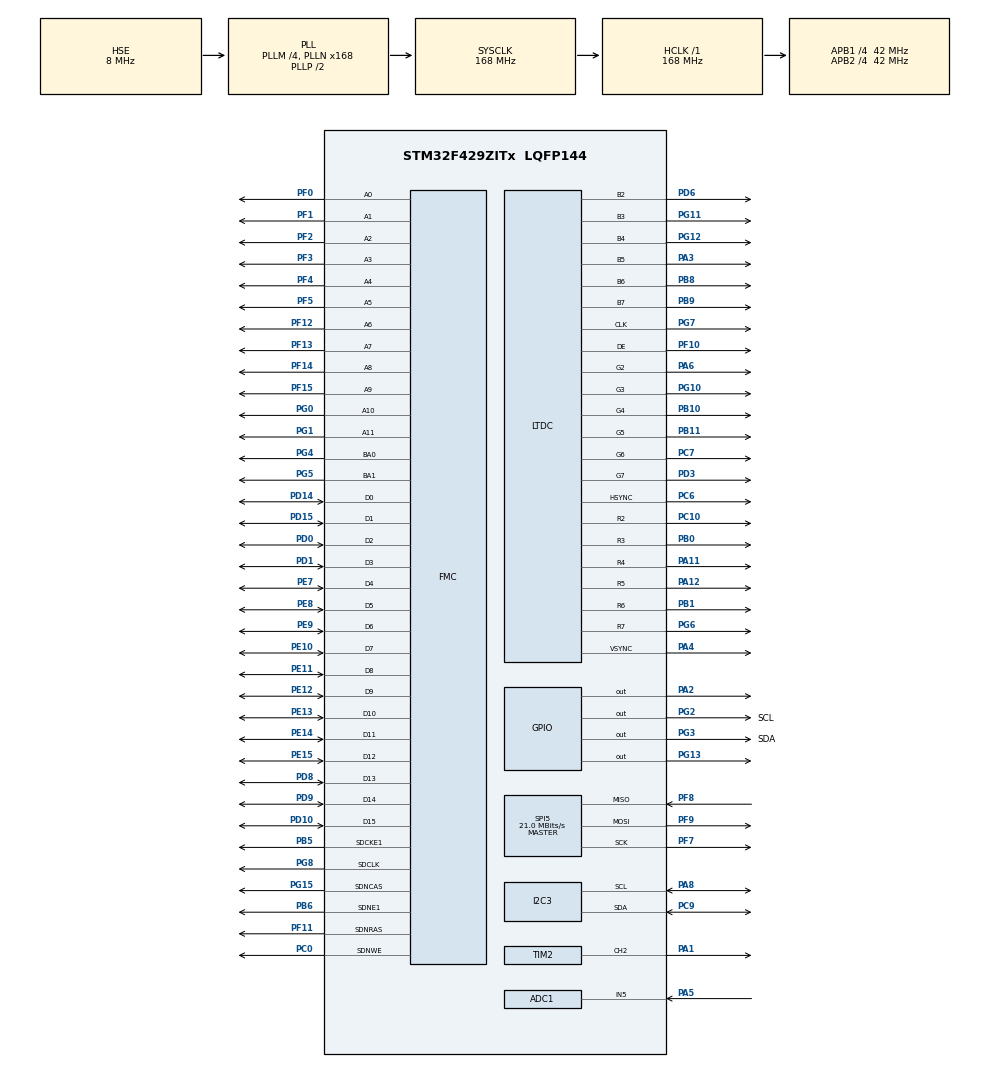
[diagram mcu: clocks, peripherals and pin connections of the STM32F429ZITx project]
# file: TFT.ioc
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ADC1.Channel-12\#ChannelRegularConversion=ADC_CHANNEL_5
ADC1.ClockPrescaler=ADC_CLOCK_SYNC_PCLK_DIV8
ADC1.NbrOfConversionFlag=1
ADC1.Rank-12\#ChannelRegularConversion=1
ADC1.SamplingTime-12\#ChannelRegularConversion=ADC_SAMPLETIME_15CYCLES
ADC1.ScanConvMode=ENABLE
ADC1.master=1
DMA2D.ColorMode=DMA2D_OUTPUT_RGB565
LTDC.ActiveH=240
LTDC.ActiveW=320
Mcu.Family=STM32F4
Mcu.Name=STM32F429ZITx
Mcu.Package=LQFP144
NVIC.PriorityGroup=NVIC_PRIORITYGROUP_4
NVIC.TIM2_IRQn=true\:0\:0\:false\:false\:true\:true
PA1.GPIO_PuPd=GPIO_NOPULL
PA1.GPIO_Speed=GPIO_SPEED_FREQ_HIGH
PA1.Signal=S_TIM2_CH2
PA11.Mode=RGB666
PA11.Signal=LTDC_R4
PA12.Mode=RGB666
PA12.Signal=LTDC_R5
PA13.Mode=Serial_Wire
PA13.Signal=SYS_JTMS-SWDIO
PA14.Mode=Serial_Wire
PA14.Signal=SYS_JTCK-SWCLK
PA2.Signal=GPIO_Output
PA3.Mode=RGB666
PA3.Signal=LTDC_B5
PA4.Mode=RGB666
PA4.Signal=LTDC_VSYNC
PA5.Signal=ADCx_IN5
PA6.Mode=RGB666
PA6.Signal=LTDC_G2
PA8.Mode=I2C
PA8.Signal=I2C3_SCL
PB0.Mode=RGB666
PB0.Signal=LTDC_R3
PB1.Mode=RGB666
PB1.Signal=LTDC_R6
PB10.Mode=RGB666
PB10.Signal=LTDC_G4
PB11.Mode=RGB666
PB11.Signal=LTDC_G5
PB5.Mode=SdramChipSelect2_1
PB5.Signal=FMC_SDCKE1
PB6.Mode=SdramChipSelect2_1
PB6.Signal=FMC_SDNE1
PB8.Mode=RGB666
PB8.Signal=LTDC_B6
PB9.Mode=RGB666
PB9.Signal=LTDC_B7
PC0.Signal=FMC_SDNWE
PC10.Mode=RGB666
PC10.Signal=LTDC_R2
PC6.Mode=RGB666
PC6.Signal=LTDC_HSYNC
PC7.Mode=RGB666
PC7.Signal=LTDC_G6
PC9.Mode=I2C
PC9.Signal=I2C3_SDA
PD0.Signal=FMC_D2_DA2
PD1.Signal=FMC_D3_DA3
PD10.Signal=FMC_D15_DA15
PD14.Signal=FMC_D0_DA0
PD15.Signal=FMC_D1_DA1
PD3.Mode=RGB666
PD3.Signal=LTDC_G7
PD6.Mode=RGB666
PD6.Signal=LTDC_B2
PD8.Signal=FMC_D13_DA13
PD9.Signal=FMC_D14_DA14
PE10.Signal=FMC_D7_DA7
PE11.Signal=FMC_D8_DA8
PE12.Signal=FMC_D9_DA9
PE13.Signal=FMC_D10_DA10
PE14.Signal=FMC_D11_DA11
PE15.Signal=FMC_D12_DA12
PE7.Signal=FMC_D4_DA4
PE8.Signal=FMC_D5_DA5
PE9.Signal=FMC_D6_DA6
PF0.Signal=FMC_A0
PF1.Signal=FMC_A1
PF10.Mode=RGB666
PF10.Signal=LTDC_DE
PF11.Signal=FMC_SDNRAS
PF12.Signal=FMC_A6
PF13.Signal=FMC_A7
PF14.Signal=FMC_A8
PF15.Signal=FMC_A9
PF2.Signal=FMC_A2
PF3.Signal=FMC_A3
PF4.Signal=FMC_A4
PF5.Signal=FMC_A5
PF7.Mode=Full_Duplex_Master
PF7.Signal=SPI5_SCK
PF8.Mode=Full_Duplex_Master
PF8.Signal=SPI5_MISO
PF9.Mode=Full_Duplex_Master
PF9.Signal=SPI5_MOSI
PG0.Signal=FMC_A10
PG1.Signal=FMC_A11
PG10.Mode=RGB666
PG10.Signal=LTDC_G3
PG11.Mode=RGB666
PG11.Signal=LTDC_B3
PG12.Mode=RGB666
PG12.Signal=LTDC_B4
PG13.Signal=GPIO_Output
PG15.Signal=FMC_SDNCAS
PG2.GPIO_Label=SCL
PG2.Signal=GPIO_Output
PG3.GPIO_Label=SDA
PG3.Signal=GPIO_Output
PG4.Signal=FMC_A14_BA0
PG5.Signal=FMC_A15_BA1
PG6.Mode=RGB666
PG6.Signal=LTDC_R7
PG7.Mode=RGB666
PG7.Signal=LTDC_CLK
PG8.Signal=FMC_SDCLK
PH0/OSC_IN.Mode=HSE-External-Oscillator
PH0/OSC_IN.Signal=RCC_OSC_IN
PH1/OSC_OUT.Mode=HSE-External-Oscillator
PH1/OSC_OUT.Signal=RCC_OSC_OUT
ProjectManager.HeapSize=0x1000
ProjectManager.StackSize=0x1000
ProjectManager.TargetToolchain=MDK-ARM V5
RCC.48MHZClocksFreq_Value=84000000
RCC.AHBFreq_Value=168000000
RCC.APB1CLKDivider=RCC_HCLK_DIV4
RCC.APB1Freq_Value=42000000
RCC.APB1TimFreq_Value=84000000
RCC.APB2CLKDivider=RCC_HCLK_DIV4
RCC.APB2Freq_Value=42000000
RCC.APB2TimFreq_Value=84000000
RCC.CortexFreq_Value=168000000
RCC.HCLKFreq_Value=168000000
RCC.HSE_VALUE=8000000
RCC.HSI_VALUE=16000000
RCC.LSE_VALUE=32768
RCC.PLLM=4
RCC.PLLN=168
RCC.PLLSAIN=216
RCC.PLLSourceVirtual=RCC_PLLSOURCE_HSE
RCC.SYSCLKFreq_VALUE=168000000
RCC.SYSCLKSource=RCC_SYSCLKSOURCE_PLLCLK
RCC.VCOOutputFreq_Value=336000000
SH.ADCx_IN5.0=ADC2_IN5
SH.ADCx_IN5.1=ADC1_IN5,IN5
SH.FMC_A0.0=FMC_A0,12b-sda1
SH.FMC_A1.0=FMC_A1,12b-sda1
SH.FMC_A10.0=FMC_A10,12b-sda1
SH.FMC_A11.0=FMC_A11,12b-sda1
SH.FMC_A14_BA0.0=FMC_BA0,FourSdramBanks1
SH.FMC_A15_BA1.0=FMC_BA1,FourSdramBanks1
SH.FMC_A2.0=FMC_A2,12b-sda1
SH.FMC_A3.0=FMC_A3,12b-sda1
SH.FMC_A4.0=FMC_A4,12b-sda1
SH.FMC_A5.0=FMC_A5,12b-sda1
SH.FMC_A6.0=FMC_A6,12b-sda1
SH.FMC_A7.0=FMC_A7,12b-sda1
SH.FMC_A8.0=FMC_A8,12b-sda1
SH.FMC_A9.0=FMC_A9,12b-sda1
SH.FMC_D0_DA0.0=FMC_D0,sd-16b-d1
SH.FMC_D10_DA10.0=FMC_D10,sd-16b-d1
SH.FMC_D11_DA11.0=FMC_D11,sd-16b-d1
SH.FMC_D12_DA12.0=FMC_D12,sd-16b-d1
SH.FMC_D13_DA13.0=FMC_D13,sd-16b-d1
SH.FMC_D14_DA14.0=FMC_D14,sd-16b-d1
SH.FMC_D15_DA15.0=FMC_D15,sd-16b-d1
SH.FMC_D1_DA1.0=FMC_D1,sd-16b-d1
SH.FMC_D2_DA2.0=FMC_D2,sd-16b-d1
SH.FMC_D3_DA3.0=FMC_D3,sd-16b-d1
SH.FMC_D4_DA4.0=FMC_D4,sd-16b-d1
SH.FMC_D5_DA5.0=FMC_D5,sd-16b-d1
SH.FMC_D6_DA6.0=FMC_D6,sd-16b-d1
SH.FMC_D7_DA7.0=FMC_D7,sd-16b-d1
SH.FMC_D8_DA8.0=FMC_D8,sd-16b-d1
SH.FMC_D9_DA9.0=FMC_D9,sd-16b-d1
SH.FMC_SDCLK.0=FMC_SDCLK,12b-sda1
SH.FMC_SDNCAS.0=FMC_SDNCAS,12b-sda1
SH.FMC_SDNRAS.0=FMC_SDNRAS,12b-sda1
SH.FMC_SDNWE.0=FMC_SDNWE,12b-sda1
SH.S_TIM2_CH2.0=TIM2_CH2,PWM Generation2 CH2
SPI5.CalculateBaudRate=21.0 MBits/s
SPI5.Direction=SPI_DIRECTION_2LINES
SPI5.Mode=SPI_MODE_MASTER
SPI5.VirtualType=VM_MASTER
TIM2.Channel-PWM\ Generation2\ CH2=TIM_CHANNEL_2
TIM2.Period=9
TIM2.Prescaler=420
TIM2.Pulse-PWM\ Generation2\ CH2=50
VP_DMA2D_VS_DMA2D.Mode=DMA2D_Activate
VP_TIM2_VS_ClockSourceINT.Mode=Internal
board=TFT

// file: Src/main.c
/**
  ******************************************************************************
  * @file           : main.c
  * @brief          : Main program body
  ******************************************************************************
  ** This notice applies to any and all portions of this file
  * that are not between comment pairs USER CODE BEGIN and
  * USER CODE END. Other portions of this file, whether
  * inserted by the user or by software development tools
  * are owned by their respective copyright owners.
  *
  * COPYRIGHT(c) 2018 STMicroelectronics
  *
  * Redistribution and use in source and binary forms, with or without modification,
  * are permitted provided that the following conditions are met:
  *   1. Redistributions of source code must retain the above copyright notice,
  *      this list of conditions and the following disclaimer.
  *   2. Redistributions in binary form must reproduce the above copyright notice,
  *      this list of conditions and the following disclaimer in the documentation
  *      and/or other materials provided with the distribution.
  *   3. Neither the name of STMicroelectronics nor the names of its contributors
  *      may be used to endorse or promote products derived from this software
  *      without specific prior written permission.
  *
  * THIS SOFTWARE IS PROVIDED BY THE COPYRIGHT HOLDERS AND CONTRIBUTORS "AS IS"
  * AND ANY EXPRESS OR IMPLIED WARRANTIES, INCLUDING, BUT NOT LIMITED TO, THE
  * IMPLIED WARRANTIES OF MERCHANTABILITY AND FITNESS FOR A PARTICULAR PURPOSE ARE
  * DISCLAIMED. IN NO EVENT SHALL THE COPYRIGHT HOLDER OR CONTRIBUTORS BE LIABLE
  * FOR ANY DIRECT, INDIRECT, INCIDENTAL, SPECIAL, EXEMPLARY, OR CONSEQUENTIAL
  * DAMAGES (INCLUDING, BUT NOT LIMITED TO, PROCUREMENT OF SUBSTITUTE GOODS OR
  * SERVICES; LOSS OF USE, DATA, OR PROFITS; OR BUSINESS INTERRUPTION) HOWEVER
  * CAUSED AND ON ANY THEORY OF LIABILITY, WHETHER IN CONTRACT, STRICT LIABILITY,
  * OR TORT (INCLUDING NEGLIGENCE OR OTHERWISE) ARISING IN ANY WAY OUT OF THE USE
  * OF THIS SOFTWARE, EVEN IF ADVISED OF THE POSSIBILITY OF SUCH DAMAGE.
  *
  ******************************************************************************
  */
#include "main.h"
#include "stm32f4xx_hal.h"
#include "adc.h"
#include "dma2d.h"
#include "i2c.h"
#include "ltdc.h"
#include "spi.h"
#include "tim.h"
#include "gpio.h"
#include "fmc.h"

/* USER CODE BEGIN Includes */

#ifndef P
/*
 * Sets an output pin
 *
 * Parameters
 *  letter - A single letter that identifies the GPIO bus
 *  pin index - A number between 0 and 8 for which pin
 *  value - a binary number that identifies low or high to drive the pin
 *
 * Usage:
 * P(G, 13, 1); // Sets pin PG13 to HIGH
 *
*/
    #define P(l,i,v)    GPIO##l->BSRR = 1<<(i+((!v)*16))
/*
 * Reads a pin from a port, returns 0 or 1
*/
    #define R(l,i)      ((GPIO##l->IDR & (1<<i))>0)
#endif

#include "stm32f429i_discovery_lcd.h"
#include "stm32f429i_discovery_sdram.h"
#include "stm32f429i_discovery_ts.h"
#include "string.h"
#include "i2c_sht15.h"
#include "slider_component.h"
#include "state_machine.h"
/* USER CODE END Includes */

/* USER CODE BEGIN PV */
/* Private variables ---------------------------------------------------------*/

/* USER CODE END PV */

void SystemClock_Config(void);

/* USER CODE BEGIN PFP */
/* Private function prototypes -----------------------------------------------*/

/* USER CODE END PFP */

/* USER CODE BEGIN 0 */
void updatePwmValue() {
	static int manual_pwm = 0;
	static int pwm_state = 0;
	int should_be_1 = (manual_pwm > pot_value/40.0f);

	if (manual_pwm < 100) {
		if (pwm_state == 0 && should_be_1) {
			P(C, 8, 1);
			pwm_state = 1;
		} else if (pwm_state == 1 && !should_be_1) {
			P(C, 8, 0);
			pwm_state = 0;
		}
		manual_pwm++;
	} else {
		manual_pwm = 0;
	}
}

int last_pwm_count; // declared to use in state_machine

void HAL_TIM_PeriodElapsedCallback(TIM_HandleTypeDef *htim)
{
	if(htim == &htim2) {
	static int sum = 0;
	static int interval = 0;
	if (R(C, 8)) {
		sum++;
	}
	interval++;
	if (interval > 100) {
		interval = 0;
		last_pwm_count = sum;
		sum = 0;
	}
	updatePwmValue();
	}
}
/* USER CODE END 0 */

int main(void)
{
  /* USER CODE BEGIN 1 */
TS_StateTypeDef TsState;
ADC_ChannelConfTypeDef sConfig;
  /* USER CODE END 1 */

  /* MCU Configuration----------------------------------------------------------*/

  /* Reset of all peripherals, Initializes the Flash interface and the Systick. */
  HAL_Init();

  /* Configure the system clock */
  SystemClock_Config();

  /* Initialize all configured peripherals */
  MX_GPIO_Init();
  MX_DMA2D_Init();
  MX_LTDC_Init();
  MX_I2C3_Init();
  MX_SPI5_Init();
  MX_FMC_Init();
  MX_TIM2_Init();
  MX_ADC1_Init();
  /* USER CODE BEGIN 2 */

  BSP_LCD_Init();
  BSP_LCD_LayerDefaultInit(LCD_BACKGROUND_LAYER,LCD_FRAME_BUFFER);
  BSP_LCD_LayerDefaultInit(LCD_FOREGROUND_LAYER,LCD_FRAME_BUFFER);
  BSP_LCD_DisplayOn();
  BSP_LCD_SelectLayer(LCD_FOREGROUND_LAYER);
  BSP_TS_Init(240, 320);
  unsigned long last_display_update = HAL_GetTick();
  init_sliders();
	init_state_machine();
	int adc_control = 0;
	HAL_TIM_Base_Start_IT(&htim2);

	GPIO_InitTypeDef GPIO_InitStruct;
	GPIO_InitStruct.Pin = GPIO_PIN_8; // SDA => PG.2
	GPIO_InitStruct.Mode = GPIO_MODE_OUTPUT_PP; //FAZ SDA COMO SAIDA
	GPIO_InitStruct.Pull = GPIO_PULLUP;
	GPIO_InitStruct.Speed = GPIO_SPEED_HIGH;
	HAL_GPIO_Init(GPIOC, &GPIO_InitStruct);

	P(C, 8, 0);
  /* USER CODE END 2 */

  /* Infinite loop */
  while (1)
  {

  /* USER CODE BEGIN 3 */
		/* start ADC CONTROL */
		if (adc_control == 0) {
			sConfig.Channel = ADC_CHANNEL_5;
			HAL_ADC_ConfigChannel(&hadc1, &sConfig);
			HAL_ADC_Start(&hadc1);
			adc_control = 1;
		} else if (adc_control == 1) {
			adc_control = 2;
		} else if (adc_control == 2) {
			if (HAL_ADC_PollForConversion(&hadc1,ADC_CHANNEL_5)==0) {
				adc_control = 3;
			}
		} else if (adc_control == 3) {
			adc_control = 4;
		} else if (adc_control == 4) {
			pot_value = HAL_ADC_GetValue(&hadc1);
			//speed.raw = pot_value; // set in state machine.h
			//speed.value = pot_value/40.48f;
			adc_control = 5;
		} else if (adc_control >= 5 && adc_control <= 10) {
			adc_control++;
		} else {
			adc_control = 0;
		}
		/* end ADC CONTROL */

        updateReadings();
        // Handle periodic drawing
        int nowMS = HAL_GetTick();
        if (nowMS-last_display_update > 50) {
            last_display_update += 50;
            // Fix very slow cycles ahead
            if (nowMS-last_display_update > 50) {
                displayState();
                last_display_update = nowMS;
            }
            displayState();
        }

        BSP_TS_GetState(&TsState);
        if(TsState.TouchDetected)
        {
            if (!last_state_was_down) {
                last_state_was_down = 1;
                processEvent(TOUCH_START, TsState.X, TsState.Y);
            } else {
                processEvent(TOUCH_MOVE, TsState.X, TsState.Y);
            }
        } else {
            if (last_state_was_down) {
                last_state_was_down = 0;
                processEvent(TOUCH_END, TsState.X, TsState.Y);
            }
        }
        HAL_Delay(10);
  }
  /* USER CODE END 3 */

}

void SystemClock_Config(void)
{

  RCC_OscInitTypeDef RCC_OscInitStruct;
  RCC_ClkInitTypeDef RCC_ClkInitStruct;
  RCC_PeriphCLKInitTypeDef PeriphClkInitStruct;

    /**Configure the main internal regulator output voltage
    */
  __HAL_RCC_PWR_CLK_ENABLE();

  __HAL_PWR_VOLTAGESCALING_CONFIG(PWR_REGULATOR_VOLTAGE_SCALE1);

    /**Initializes the CPU, AHB and APB busses clocks
    */
  RCC_OscInitStruct.OscillatorType = RCC_OSCILLATORTYPE_HSE;
  RCC_OscInitStruct.HSEState = RCC_HSE_ON;
  RCC_OscInitStruct.PLL.PLLState = RCC_PLL_ON;
  RCC_OscInitStruct.PLL.PLLSource = RCC_PLLSOURCE_HSE;
  RCC_OscInitStruct.PLL.PLLM = 4;
  RCC_OscInitStruct.PLL.PLLN = 168;
  RCC_OscInitStruct.PLL.PLLP = RCC_PLLP_DIV2;
  RCC_OscInitStruct.PLL.PLLQ = 4;
  if (HAL_RCC_OscConfig(&RCC_OscInitStruct) != HAL_OK)
  {
    _Error_Handler(__FILE__, __LINE__);
  }

    /**Initializes the CPU, AHB and APB busses clocks
    */
  RCC_ClkInitStruct.ClockType = RCC_CLOCKTYPE_HCLK|RCC_CLOCKTYPE_SYSCLK
                              |RCC_CLOCKTYPE_PCLK1|RCC_CLOCKTYPE_PCLK2;
  RCC_ClkInitStruct.SYSCLKSource = RCC_SYSCLKSOURCE_PLLCLK;
  RCC_ClkInitStruct.AHBCLKDivider = RCC_SYSCLK_DIV1;
  RCC_ClkInitStruct.APB1CLKDivider = RCC_HCLK_DIV4;
  RCC_ClkInitStruct.APB2CLKDivider = RCC_HCLK_DIV4;

  if (HAL_RCC_ClockConfig(&RCC_ClkInitStruct, FLASH_LATENCY_5) != HAL_OK)
  {
    _Error_Handler(__FILE__, __LINE__);
  }

  PeriphClkInitStruct.PeriphClockSelection = RCC_PERIPHCLK_LTDC;
  PeriphClkInitStruct.PLLSAI.PLLSAIN = 216;
  PeriphClkInitStruct.PLLSAI.PLLSAIR = 2;
  PeriphClkInitStruct.PLLSAIDivR = RCC_PLLSAIDIVR_2;
  if (HAL_RCCEx_PeriphCLKConfig(&PeriphClkInitStruct) != HAL_OK)
  {
    _Error_Handler(__FILE__, __LINE__);
  }

    /**Configure the Systick interrupt time
    */
  HAL_SYSTICK_Config(HAL_RCC_GetHCLKFreq()/1000);

    /**Configure the Systick
    */
  HAL_SYSTICK_CLKSourceConfig(SYSTICK_CLKSOURCE_HCLK);

  /* SysTick_IRQn interrupt configuration */
  HAL_NVIC_SetPriority(SysTick_IRQn, 0, 0);
}

void _Error_Handler(char *file, int line)
{
  while(1)
  {
  }
}

/************************ (C) COPYRIGHT STMicroelectronics *****END OF FILE****/
